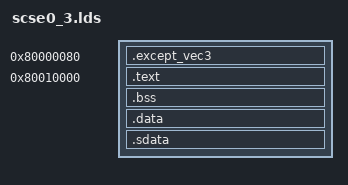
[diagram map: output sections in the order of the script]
OUTPUT_ARCH(mips)              /* 目标架构为 MIPS，用于指导链接器选择合适的 ABI/指令集 */
ENTRY(_start)                  /* 程序入口符号设置为 _start，对应启动代码的入口 */

SECTIONS                       /* 开始定义输出节的布局规则（链接脚本主体） */
{
  . = 0x80000080;              /* 将位置计数器（location counter）设置到 0x80000080 */
  .except_vec3 : {             /* 定义输出节 .except_vec3，放置异常向量表代码 */
	*(.text.exc_vec3)         /* 收集所有输入目标中的 .text.exc_vec3 节内容 */
    }

  . = 0x80010000;              /* 将位置计数器调整到 0x80010000（常规文本起始） */
  .text : {                    /* 定义输出节 .text，放置可执行指令 */
        *(.text)               /* 收集所有输入目标的 .text 节 */
    }

  .bss  : {                    /* 定义未初始化数据节 .bss（占位零填充） */
   *(.bss)                      /* 收集所有输入目标的 .bss 节 */
   }

  .data : {                    /* 定义已初始化数据节 .data */
	*(.data)                   /* 收集所有输入目标的 .data 节 */
	}

  .sdata : {                   /* 定义小数据节 .sdata（小对象优化放置） */
    *(.sdata)                  /* 收集所有输入目标的 .sdata 节 */
  }

  . = 0x80400000;              /* 将位置计数器设置到 0x80400000（高地址区域） */

   end = . ;                   /* 定义符号 end 等于当前位置，标记镜像末尾 */
}
